# STM32N645 register map
File version: 1.0
CPU: CM55 r0p1, little endian, no MPU, FPU, vendor SysTick, 8 interrupt priority bits
Registers are 32-bit, read-write, reset 0x0 unless marked. A register's access mark holds for its fields unless they carry their own. Offsets are from the block's base; [hi:lo] are bit positions; {n}, {i} and the like mark numbered series.

## CRC — Cyclic redundancy check calculation unit
Base 0x46024C00
Same registers: CRC_S 0x56024C00
0x00 DR reset 0xFFFFFFFF — CRC data register
  [31:0] DR — Data register bits
0x04 IDR — CRC independent data register
  [31:0] IDR — General-purpose 32-bit data register bits
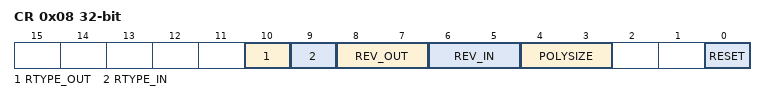
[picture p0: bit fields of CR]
0x08 CR — CRC control register
  [10] RTYPE_OUT — Reverse type output
  [9] RTYPE_IN — Reverse type input
  [8:7] REV_OUT — Reverse output data
  [6:5] REV_IN — Reverse input data
  [4:3] POLYSIZE — Polynomial size
  [0] RESET — RESET bit
0x10 INIT reset 0xFFFFFFFF — CRC initial value
  [31:0] CRC_INIT — Programmable initial CRC value
0x14 POL reset 0x4C11DB7 — CRC polynomial
  [31:0] POL — Programmable polynomial

## DBGMCU — Microcontroller debug unit
Base 0x44001000
Same registers: DBGMCU_S 0x54001000
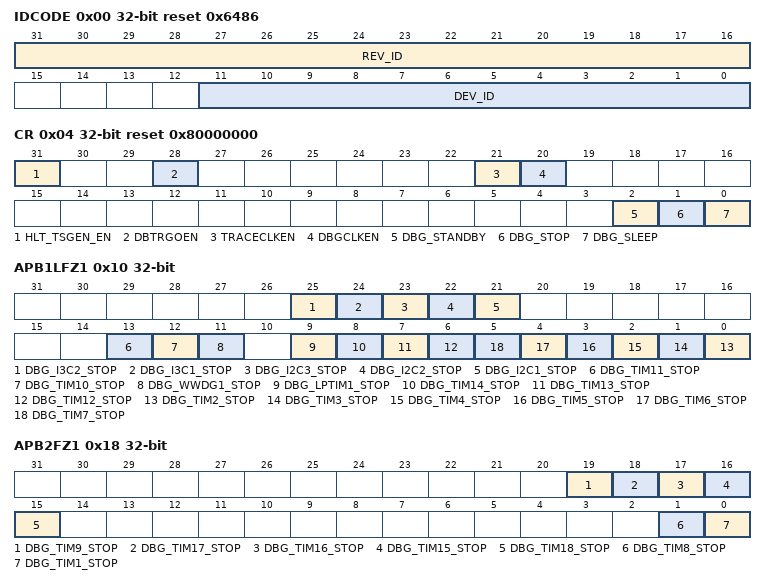
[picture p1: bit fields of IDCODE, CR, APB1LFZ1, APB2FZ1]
0x00 IDCODE ro reset 0x6486 (reset mask 0xFFFF) — DBGMCU identity code register
  [31:16] REV_ID — Revision
  [11:0] DEV_ID — Device ID
0x04 CR reset 0x80000000 — DBGMCU configuration register
  [31] HLT_TSGEN_EN — TSGEN halt enable
  [28] DBTRGOEN — DBTRGIO connection control
  [21] TRACECLKEN — TPIU export clock enable through software
  [20] DBGCLKEN — Debug clock enable through software
  [2] DBG_STANDBY — Allow debug in Standby mode
  [1] DBG_STOP — Allow debug in Stop mode
  [0] DBG_SLEEP — Allow debug in Sleep mode
0x10 APB1LFZ1 — DBGMCU APB1L peripheral freeze register
  [25] DBG_I3C2_STOP — I3C2 SMBUS timeout stop in debug
  [24] DBG_I3C1_STOP — I3C1 SMBUS timeout stop in debug
  [23] DBG_I2C3_STOP — I2C3 SMBUS timeout stop in debug
  [22] DBG_I2C2_STOP — I2C2 SMBUS timeout stop in debug
  [21] DBG_I2C1_STOP — I2C1 SMBUS timeout stop in debug
  [13] DBG_TIM11_STOP — TIM11 stop in debug
  [12] DBG_TIM10_STOP — TIM10 stop in debug
  [11] DBG_WWDG1_STOP — WWDG1 stop in debug
  [9] DBG_LPTIM1_STOP — LPTIM1 stop in debug
  [8] DBG_TIM14_STOP — TIM14 stop in debug
  [7] DBG_TIM13_STOP — TIM13 stop in debug
  [6] DBG_TIM12_STOP — TIM12 stop in debug
  [n-2] DBG_TIM{n}_STOP (n=2..7) — TIM{n} stop in debug
0x14 APB1HFZ1 — DBGMCU APB1H peripheral freeze register
  [8] DBG_FDCAN_STOP — FDCAN stop in debug
0x18 APB2FZ1 — DBGMCU APB2 peripheral freeze register
  [19] DBG_TIM9_STOP — TIM9 stop in debug
  [18] DBG_TIM17_STOP — TIM17 stop in debug
  [17] DBG_TIM16_STOP — TIM16 stop in debug
  [16] DBG_TIM15_STOP — TIM15 stop in debug
  [15] DBG_TIM18_STOP — TIM18 stop in debug
  [1] DBG_TIM8_STOP — TIM8 stop in debug
  [0] DBG_TIM1_STOP — TIM1 stop in debug
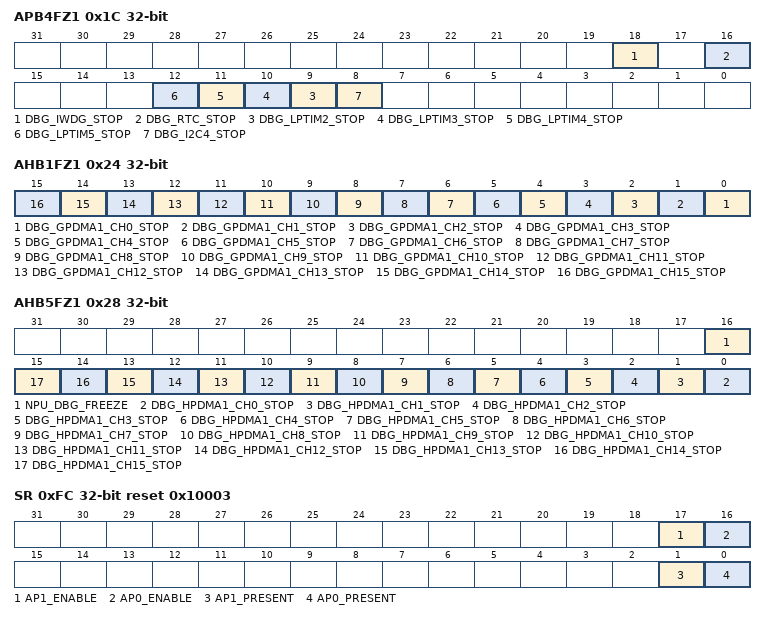
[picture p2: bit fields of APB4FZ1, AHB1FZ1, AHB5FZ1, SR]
0x1C APB4FZ1 — DBGMCU APB4 peripheral freeze register
  [18] DBG_IWDG_STOP — WWDG stop in debug
  [16] DBG_RTC_STOP — RTC clock is suspended in debug
  [n+7] DBG_LPTIM{n}_STOP (n=2..5) — LPTIM{n} stop in debug
  [8] DBG_I2C4_STOP — I2C4 stop in debug
0x20 APB5FZ1 — DBGMCU APB5 peripheral freeze register
  [4] DBG_GFXTIM_STOP — GFXTIM stop in debug
0x24 AHB1FZ1 — DBGMCU AHB1 peripheral freeze register
  [n] DBG_GPDMA1_CH{n}_STOP (n=0..15) — GPDMA1_CHn suspend in debug
0x28 AHB5FZ1 — DBGMCU AHB5 peripheral freeze register
  [16] NPU_DBG_FREEZE — NPU stop in debug mode
  [n] DBG_HPDMA1_CH{n}_STOP (n=0..15) — HPDMA3_CHn suspend in debug
0xFC SR ro reset 0x10003 — DBGMCU status register
  [17] AP1_ENABLE — Access point 1 enable
  [16] AP0_ENABLE — Access point 0 enable
  [1] AP1_PRESENT — Access point 1 presence
  [0] AP0_PRESENT — Access point 0 presence
0x100 DBG_AUTH_HOST — DBGMCU host authentication register
  [31:0] MESSAGE — Mailbox between debugger and processor
0x104 DBG_AUTH_DEV — DBGMCU device authentication register
  [31:0] MESSAGE — Mailbox between debugger and processor
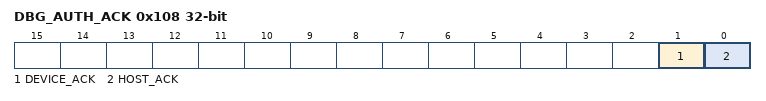
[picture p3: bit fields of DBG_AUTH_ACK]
0x108 DBG_AUTH_ACK ro — DBGMCU message read acknowledge authentication register
  [1] DEVICE_ACK — Access status to DBG_AUTH_DEV register
  [0] HOST_ACK — Access status to DBG_AUTH_HOST register
